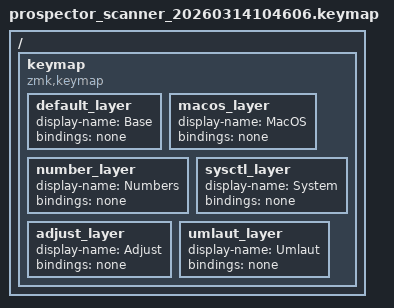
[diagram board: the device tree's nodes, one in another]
// Basic import
#include <behaviors.dtsi>
#include <dt-bindings/zmk/keys.h>
#include <dt-bindings/zmk/bt.h>
#include <dt-bindings/zmk/outputs.h>

// Layers
#define DEFAULT 0
#define MACOS   1
#define NUMBER  2
#define SYSCTL  3
#define ADJUST  4
#define UMLAUT  5

/ {
    keymap {
        compatible = "zmk,keymap";

                // ── Layer 0: DEFAULT ─────────────────────────────────────────
                default_layer {
                    display-name = "Base";
                        bindings = <
                        <&none>
                        >;
                };

                                // ── Layer 1: MacOS ──────────────────────────────────────────
                macos_layer {
                    display-name = "MacOS";
                        bindings = <
                        <&none>
                        >;
                };

                // ── Layer 3: NUMBER ──────────────────────────────────────────
                number_layer {
                    display-name = "Numbers";
                        bindings = <
                        <&none>
                        >;
                };

                // ── Layer 4: SYSCTL ──────────────────────────────────────────
                sysctl_layer {
                    display-name = "System";
                        bindings = <
                        <&none>
                        >;
                };

                // ── Layer 5: ADJUST ──────────────────────────────────────────
                adjust_layer {
                    display-name = "Adjust";
                        bindings = <
                        <&none>
                        >;
                };

                // ── Layer 6: UMLAUT ──────────────────────────────────────────
                umlaut_layer {
                    display-name = "Umlaut";
                        bindings = <
                        <&none>
                        >;
                };
        };
};
